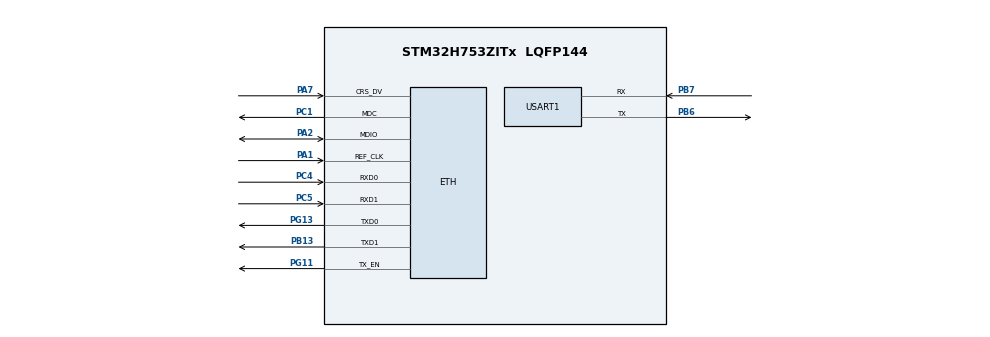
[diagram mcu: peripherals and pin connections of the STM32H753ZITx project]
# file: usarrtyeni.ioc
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CORTEX_M7.CPU_DCache=Disabled
CORTEX_M7.CPU_ICache=Disabled
CORTEX_M7.MPU_Control=MPU_PRIVILEGED_DEFAULT
CORTEX_M7.default_mode_Activation=1
ETH.MediaInterface=HAL_ETH_RMII_MODE
LWIP.BSP.number=1
LWIP.IP_ADDRESS=192.168.001.010
LWIP.LWIP_DHCP=0
LWIP.NETMASK_ADDRESS=255.255.255.000
LWIP.Version=v2.2.1_Cube
LWIP0.BSP.STBoard=false
LWIP0.BSP.api=BSP_COMPONENT_DRIVER
LWIP0.BSP.component=LAN8742
LWIP0.BSP.instance=LAN8742
LWIP0.BSP.name=Driver_PHY
LWIP0.BSP.semaphore=S_LAN8742
LWIP0.BSP.solution=LAN8742
Mcu.Family=STM32H7
Mcu.Name=STM32H753ZITx
Mcu.Package=LQFP144
NUCLEO-H753ZI.BUTTON=1
NUCLEO-H753ZI.LD1=true
NUCLEO-H753ZI.LD2=true
NUCLEO-H753ZI.LD3=true
NUCLEO-H753ZI.VCP=true
NVIC.ETH_IRQn=true\:0\:0\:false\:false\:true\:true\:true\:true
NVIC.EXTI15_10_IRQn=true\:0\:0\:false\:false\:true\:false\:true\:true
NVIC.PriorityGroup=NVIC_PRIORITYGROUP_4
NVIC.USART1_IRQn=true\:0\:0\:false\:false\:true\:true\:true\:true
PA1.Mode=RMII
PA1.Signal=ETH_REF_CLK
PA2.Mode=RMII
PA2.Signal=ETH_MDIO
PA7.Mode=RMII
PA7.Signal=ETH_CRS_DV
PB13.Mode=RMII
PB13.Signal=ETH_TXD1
PB6.Mode=Asynchronous
PB6.Signal=USART1_TX
PB7.Mode=Asynchronous
PB7.Signal=USART1_RX
PC1.Mode=RMII
PC1.Signal=ETH_MDC
PC14-OSC32_IN\ (OSC32_IN).Mode=LSE-External-Oscillator
PC14-OSC32_IN\ (OSC32_IN).Signal=RCC_OSC32_IN
PC15-OSC32_OUT\ (OSC32_OUT).Mode=LSE-External-Oscillator
PC15-OSC32_OUT\ (OSC32_OUT).Signal=RCC_OSC32_OUT
PC4.Mode=RMII
PC4.Signal=ETH_RXD0
PC5.Mode=RMII
PC5.Signal=ETH_RXD1
PD8.Signal=USART3_TX
PD9.Signal=USART3_RX
PG11.Mode=RMII
PG11.Signal=ETH_TX_EN
PG13.Mode=RMII
PG13.Signal=ETH_TXD0
PH0-OSC_IN\ (PH0).Mode=HSE-External-Oscillator
PH0-OSC_IN\ (PH0).Signal=RCC_OSC_IN
PH1-OSC_OUT\ (PH1).Mode=HSE-External-Oscillator
PH1-OSC_OUT\ (PH1).Signal=RCC_OSC_OUT
ProjectManager.HeapSize=0x200
ProjectManager.StackSize=0x400
ProjectManager.TargetToolchain=STM32CubeIDE
RCC.ADCFreq_Value=16125000
RCC.APB1Freq_Value=120000000
RCC.APB2Freq_Value=120000000
RCC.APB3Freq_Value=120000000
RCC.APB4Freq_Value=120000000
RCC.CortexFreq_Value=480000000
RCC.D1PPRE=RCC_APB3_DIV2
RCC.D2PPRE1=RCC_APB1_DIV2
RCC.D2PPRE2=RCC_APB2_DIV2
RCC.D3PPRE=RCC_APB4_DIV2
RCC.DIVM1=1
RCC.DIVN1=120
RCC.DIVQ1=4
RCC.HCLKFreq_Value=240000000
RCC.HPRE=RCC_HCLK_DIV2
RCC.HSE_VALUE=8000000
RCC.PLLFRACN=0
RCC.PLLSourceVirtual=RCC_PLLSOURCE_HSE
RCC.PWR_Regulator_Voltage_Scale=PWR_REGULATOR_VOLTAGE_SCALE0
RCC.SYSCLKFreq_VALUE=480000000
RCC.SYSCLKSource=RCC_SYSCLKSOURCE_PLLCLK
RCC.USBFreq_Value=240000000
USART1.VirtualMode-Asynchronous=VM_ASYNC
VP_LWIP_VS_Enabled.Mode=Enabled
VP_MEMORYMAP_VS_MEMORYMAP.Mode=CurAppReg
VP_NUCLEO-H753ZI_VS_BSP_COMMON.Mode=COMMON
board=NUCLEO-H753ZI

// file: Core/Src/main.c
/* USER CODE BEGIN Header */
/**
  ******************************************************************************
  * @file           : main.c
  * @brief          : Main program body (UART to Ethernet TCP Telemetry Bridge)
  ******************************************************************************
  * @attention
  *
  * Copyright (c) 2026 STMicroelectronics.
  * All rights reserved.
  *
  * This software is licensed under terms that can be found in the LICENSE file
  * in the root directory of this software component.
  * If no LICENSE file comes with this software, it is provided AS-IS.
  *
  ******************************************************************************
  */
/* USER CODE END Header */
#include "main.h"
#include "lwip.h"

/* USER CODE BEGIN Includes */
#include "tcp_telemetry_bridge.h"  // TCP Sunucu ve LwIP işleyici
#include "telemetry_parser.h"      // UART MAVLink ayrıştırıcı ve tampon yönetimi
#include "status_led.h"           // Donanım ve ağ durum LED göstergeleri
/* USER CODE END Includes */

COM_InitTypeDef BspCOMInit;

UART_HandleTypeDef huart1;

void SystemClock_Config(void);
static void MPU_Config(void);
static void MX_GPIO_Init(void);
static void MX_USART1_UART_Init(void);

int main(void)
{

  /* USER CODE BEGIN 1 */
  /* STM32H7 Ethernet DMA önbellek (Cache) çakışmasını önlemek için D-Cache kapatılır */
  SCB_DisableDCache();
  /* USER CODE END 1 */

  /* MPU Configuration--------------------------------------------------------*/
  MPU_Config();

  /* MCU Configuration--------------------------------------------------------*/

  /* Reset of all peripherals, Initializes the Flash interface and the Systick. */
  HAL_Init();

  /* Configure the system clock */
  SystemClock_Config();

  /* Initialize all configured peripherals */
  MX_GPIO_Init();
  MX_USART1_UART_Init();
  MX_LWIP_Init();

  /* USER CODE BEGIN 2 */
  /* --- Uygulama Modüllerinin Başlatılması --- */

  // 1. Durum LED'lerini hazırla
  StatusLED_Init();

  // 2. TCP Sunucuyu Port 5000 üzerinde dinlemeye al
  TCP_Bridge_Init(5000);

  // 3. UART Telemetri dinlemesini ve kesmelerini başlat
  Telemetry_Init(&huart1);
  /* USER CODE END 2 */

  /* Initialize COM1 port (115200, 8 bits, no parity) */
  BspCOMInit.BaudRate   = 115200;
  BspCOMInit.WordLength = COM_WORDLENGTH_8B;
  BspCOMInit.StopBits   = COM_STOPBITS_1;
  BspCOMInit.Parity     = COM_PARITY_NONE;
  BspCOMInit.HwFlowCtl  = COM_HWCONTROL_NONE;
  if (BSP_COM_Init(COM1, &BspCOMInit) != BSP_ERROR_NONE)
  {
    Error_Handler();
  }

  /* Infinite loop */
  /* USER CODE BEGIN WHILE */
  while (1)
  {
    /* 1. LwIP Paket İşleme Döngüsü (PING ve TCP Akışı için Zorunlu) */
    TCP_Bridge_Process();

    /* 2. Donanım ve Ağ Durum LED'lerinin Güncellenmesi */
    StatusLED_UpdateNetworkStatus();

    /* USER CODE END WHILE */

  }
}

void SystemClock_Config(void)
{
  RCC_OscInitTypeDef RCC_OscInitStruct = {0};
  RCC_ClkInitTypeDef RCC_ClkInitStruct = {0};

  /** Supply configuration update enable
  */
  HAL_PWREx_ConfigSupply(PWR_LDO_SUPPLY);

  /** Configure the main internal regulator output voltage
  */
  __HAL_PWR_VOLTAGESCALING_CONFIG(PWR_REGULATOR_VOLTAGE_SCALE0);

  while(!__HAL_PWR_GET_FLAG(PWR_FLAG_VOSRDY)) {}

  /** Initializes the RCC Oscillators according to the specified parameters
  * in the RCC_OscInitTypeDef structure.
  */
  RCC_OscInitStruct.OscillatorType = RCC_OSCILLATORTYPE_HSE;
  RCC_OscInitStruct.HSEState = RCC_HSE_ON;
  RCC_OscInitStruct.PLL.PLLState = RCC_PLL_ON;
  RCC_OscInitStruct.PLL.PLLSource = RCC_PLLSOURCE_HSE;
  RCC_OscInitStruct.PLL.PLLM = 1;
  RCC_OscInitStruct.PLL.PLLN = 120;
  RCC_OscInitStruct.PLL.PLLP = 2;
  RCC_OscInitStruct.PLL.PLLQ = 4;
  RCC_OscInitStruct.PLL.PLLR = 2;
  RCC_OscInitStruct.PLL.PLLRGE = RCC_PLL1VCIRANGE_3;
  RCC_OscInitStruct.PLL.PLLVCOSEL = RCC_PLL1VCOWIDE;
  RCC_OscInitStruct.PLL.PLLFRACN = 0;
  if (HAL_RCC_OscConfig(&RCC_OscInitStruct) != HAL_OK)
  {
    Error_Handler();
  }

  /** Initializes the CPU, AHB and APB buses clocks
  */
  RCC_ClkInitStruct.ClockType = RCC_CLOCKTYPE_HCLK|RCC_CLOCKTYPE_SYSCLK
                              |RCC_CLOCKTYPE_PCLK1|RCC_CLOCKTYPE_PCLK2
                              |RCC_CLOCKTYPE_D3PCLK1|RCC_CLOCKTYPE_D1PCLK1;
  RCC_ClkInitStruct.SYSCLKSource = RCC_SYSCLKSOURCE_PLLCLK;
  RCC_ClkInitStruct.SYSCLKDivider = RCC_SYSCLK_DIV1;
  RCC_ClkInitStruct.AHBCLKDivider = RCC_HCLK_DIV2;
  RCC_ClkInitStruct.APB3CLKDivider = RCC_APB3_DIV2;
  RCC_ClkInitStruct.APB1CLKDivider = RCC_APB1_DIV2;
  RCC_ClkInitStruct.APB2CLKDivider = RCC_APB2_DIV2;
  RCC_ClkInitStruct.APB4CLKDivider = RCC_APB4_DIV2;

  if (HAL_RCC_ClockConfig(&RCC_ClkInitStruct, FLASH_LATENCY_4) != HAL_OK)
  {
    Error_Handler();
  }
}

static void MX_USART1_UART_Init(void)
{

  huart1.Instance = USART1;
  huart1.Init.BaudRate = 115200;
  huart1.Init.WordLength = UART_WORDLENGTH_8B;
  huart1.Init.StopBits = UART_STOPBITS_1;
  huart1.Init.Parity = UART_PARITY_NONE;
  huart1.Init.Mode = UART_MODE_TX_RX;
  huart1.Init.HwFlowCtl = UART_HWCONTROL_NONE;
  huart1.Init.OverSampling = UART_OVERSAMPLING_16;
  huart1.Init.OneBitSampling = UART_ONE_BIT_SAMPLE_DISABLE;
  huart1.Init.ClockPrescaler = UART_PRESCALER_DIV1;
  huart1.AdvancedInit.AdvFeatureInit = UART_ADVFEATURE_NO_INIT;
  if (HAL_UART_Init(&huart1) != HAL_OK)
  {
    Error_Handler();
  }
  if (HAL_UARTEx_SetTxFifoThreshold(&huart1, UART_TXFIFO_THRESHOLD_1_8) != HAL_OK)
  {
    Error_Handler();
  }
  if (HAL_UARTEx_SetRxFifoThreshold(&huart1, UART_RXFIFO_THRESHOLD_1_8) != HAL_OK)
  {
    Error_Handler();
  }
  if (HAL_UARTEx_DisableFifoMode(&huart1) != HAL_OK)
  {
    Error_Handler();
  }

}

static void MX_GPIO_Init(void)
{

  /* GPIO Ports Clock Enable */
  __HAL_RCC_GPIOC_CLK_ENABLE();
  __HAL_RCC_GPIOH_CLK_ENABLE();
  __HAL_RCC_GPIOA_CLK_ENABLE();
  __HAL_RCC_GPIOB_CLK_ENABLE();
  __HAL_RCC_GPIOG_CLK_ENABLE();

}

/* USER CODE BEGIN 4 */
/**
  * @brief HAL UART RX Callback (Kesme Modül Yönlendirmesi)
  */
void HAL_UART_RxCpltCallback(UART_HandleTypeDef *huart)
{
    Telemetry_OnUartRxByte(huart);
}

/**
  * @brief HAL UART Error Callback (Hata Temizleme Modül Yönlendirmesi)
  */
void HAL_UART_ErrorCallback(UART_HandleTypeDef *huart)
{
    Telemetry_OnUartError(huart);
}
/* USER CODE END 4 */

 /* MPU Configuration */

void MPU_Config(void)
{
  MPU_Region_InitTypeDef MPU_InitStruct = {0};

  /* Disables the MPU */
  HAL_MPU_Disable();

  /** Initializes and configures the Region and the memory to be protected
  */
  MPU_InitStruct.Enable = MPU_REGION_ENABLE;
  MPU_InitStruct.Number = MPU_REGION_NUMBER0;
  MPU_InitStruct.BaseAddress = 0x0;
  MPU_InitStruct.Size = MPU_REGION_SIZE_4GB;
  MPU_InitStruct.SubRegionDisable = 0x87;
  MPU_InitStruct.TypeExtField = MPU_TEX_LEVEL0;
  MPU_InitStruct.AccessPermission = MPU_REGION_NO_ACCESS;
  MPU_InitStruct.DisableExec = MPU_INSTRUCTION_ACCESS_DISABLE;
  MPU_InitStruct.IsShareable = MPU_ACCESS_SHAREABLE;
  MPU_InitStruct.IsCacheable = MPU_ACCESS_NOT_CACHEABLE;
  MPU_InitStruct.IsBufferable = MPU_ACCESS_NOT_BUFFERABLE;

  HAL_MPU_ConfigRegion(&MPU_InitStruct);
  /* Enables the MPU */
  HAL_MPU_Enable(MPU_PRIVILEGED_DEFAULT);

}

void Error_Handler(void)
{
  __disable_irq();
  while (1)
  {
  }
}
